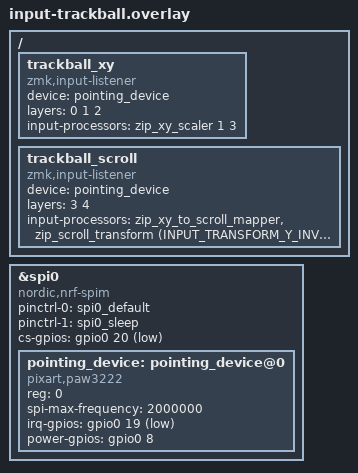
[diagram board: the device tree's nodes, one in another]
&spi0 {
    status = "okay";
    compatible = "nordic,nrf-spim";
    pinctrl-0 = <&spi0_default>;
    pinctrl-1 = <&spi0_sleep>;
    pinctrl-names = "default", "sleep";
    cs-gpios = <&gpio0 20 GPIO_ACTIVE_LOW>;

    pointing_device: pointing_device@0 {
        status = "okay";
        compatible = "pixart,paw3222";
        reg = <0>;
        spi-max-frequency = <2000000>;
        irq-gpios = <&gpio0 19 GPIO_ACTIVE_LOW>;
        power-gpios = <&gpio0 8 (GPIO_ACTIVE_HIGH | NRF_GPIO_DRIVE_H0H1)>;
    };
};

/ {
    // 1つ目: 通常時のポインティング設定（カーソル移動用）
    trackball_xy {
        compatible = "zmk,input-listener";
        device = <&pointing_device>;
        layers = <0 1 2>;
        // ここで通常のカーソル感度を調整します
        input-processors = <&zip_xy_scaler 1 3>;
    };

    // 2つ目: スクロール時の設定（スクロール用）
    trackball_scroll {
        compatible = "zmk,input-listener";
        device = <&pointing_device>;
        layers = <3 4>;
        input-processors = 
            <&zip_xy_to_scroll_mapper>, 
            <&zip_scroll_transform (INPUT_TRANSFORM_Y_INVERT)>;
    };
};
